# CONTROLSS_PWMSYNCOUTXBAR_CONTROLSS_PWMSYNCOUTXBAR register map
Vendor: Texas Instruments
Peripheral module from a debugger description file (folder AM263).
Registers are 32-bit, read-write, reset 0x0 unless marked. A register's access mark holds for its fields unless they carry their own. Offsets are as the file gives them; lines under a group give offsets from that group; [hi:lo] are bit positions; {n}, {i} and the like mark numbered series; 'fields as' and 'values as' point back to an identical list; <NAME> marks a mode.

## CONTROLSS_PWMSYNCOUTXBAR_CONTROLSS_PWMSYNCOUTXBAR
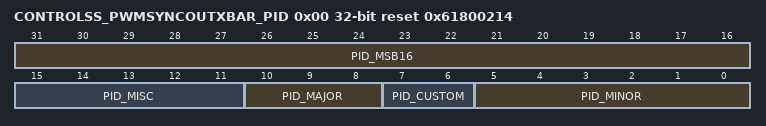
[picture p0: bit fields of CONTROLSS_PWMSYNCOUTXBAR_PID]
0x00 CONTROLSS_PWMSYNCOUTXBAR_PID ro reset 0x61800214
  [31:16] PID_MSB16 — Not Defined
  [15:11] PID_MISC — Not Defined
  [10:8] PID_MAJOR — Not Defined
  [7:6] PID_CUSTOM — Not Defined
  [5:0] PID_MINOR — Not Defined
{0x100+0x40*i} CONTROLSS_PWMSYNCOUTXBAR_PWMSYNCOUTXBAR{i}_G0 (i=0..3)
  [31:0] SEL — ETPWM pwmsyncout xbar{i} select1: PWM[x] SYNCOUT selected0: PWM[x] SYNCOUT is de-selected
